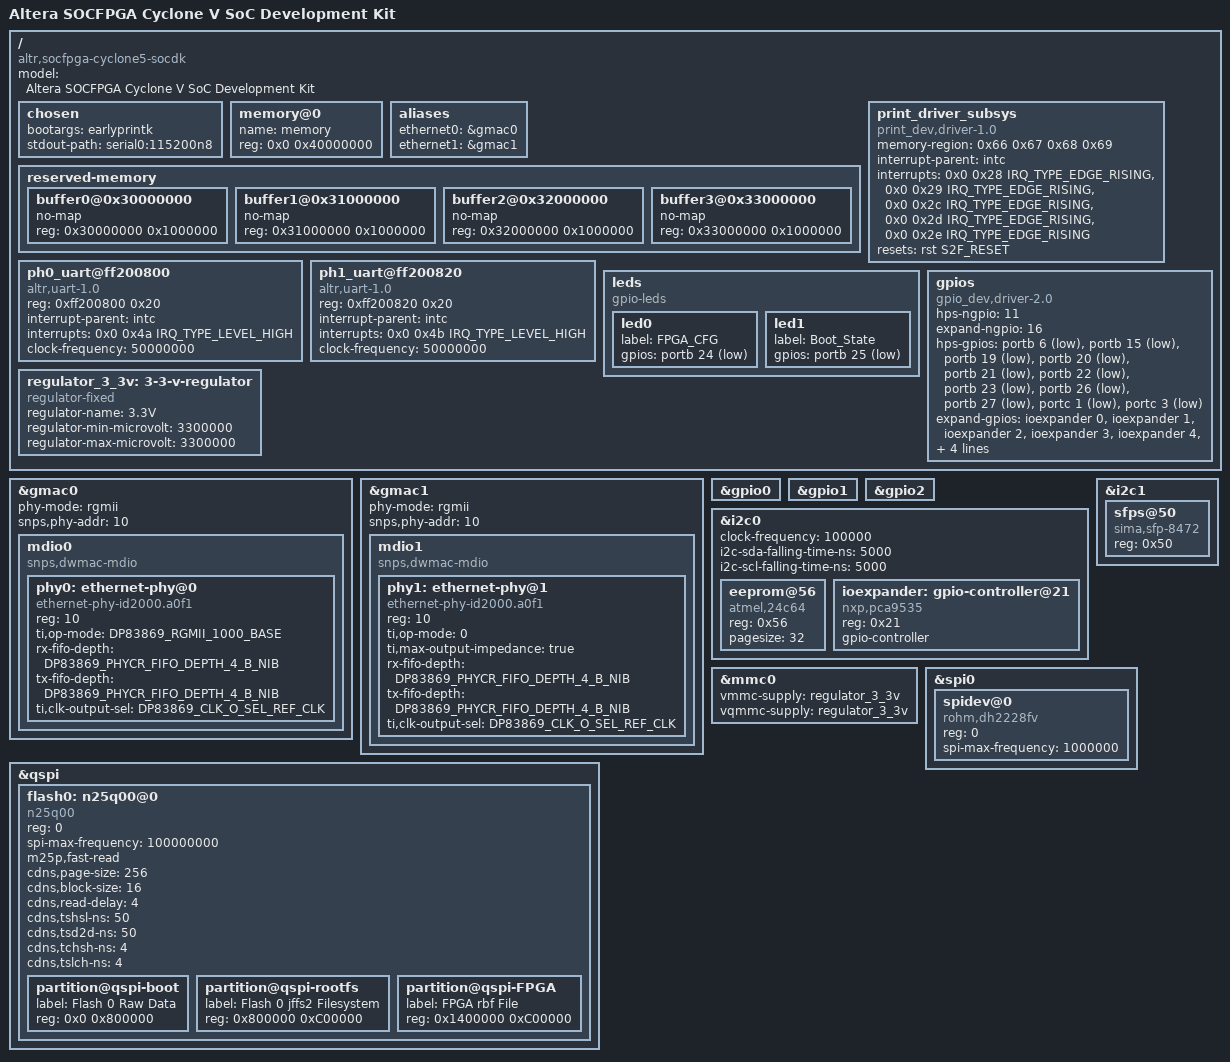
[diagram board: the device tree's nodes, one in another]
// SPDX-License-Identifier: GPL-2.0+
/*
 * Copyright (C) 2012 Altera Corporation <www.altera.com>
 */

#include "socfpga_cyclone5.dtsi"

#include <dt-bindings/gpio/gpio.h>
#include <dt-bindings/net/ti-dp83869.h>
#include <dt-bindings/interrupt-controller/irq.h>

/ {
	model = "Altera SOCFPGA Cyclone V SoC Development Kit";
	compatible = "altr,socfpga-cyclone5-socdk", "altr,socfpga-cyclone5", "altr,socfpga";

	chosen {
		bootargs = "earlyprintk";
		stdout-path = "serial0:115200n8";
	};

	memory@0 {
		name = "memory";
		device_type = "memory";
		reg = <0x0 0x40000000>; /* 1GB */
	};

	aliases {
		/* this allow the ethaddr uboot environmnet variable contents
		 * to be added to the gmac1 device tree blob.
		 */
		ethernet0 = &gmac0;
		ethernet1 = &gmac1;
	};

	reserved-memory {
		#address-cells = <0x1>;
		#size-cells = <0x1>;
		ranges;

		/* 上行ph0 */
		buffer0@0x30000000 {
			no-map;
			reg = <0x30000000 0x1000000>;
			linux,phandle = <0x66>;
			phandle = <0x66>;
		};
		
		/* 上行ph1 */
		buffer1@0x31000000 {
			no-map;
			reg = <0x31000000 0x1000000>;
			linux,phandle = <0x67>;
			phandle = <0x67>;
		};

		/* 下行ph0 */
		buffer2@0x32000000 {
			no-map;
			reg = <0x32000000 0x1000000>;
			linux,phandle = <0x68>;
			phandle = <0x68>;
		};

		/* 下行ph1 */
		buffer3@0x33000000 {
			no-map;
			reg = <0x33000000 0x1000000>;
			linux,phandle = <0x69>;
			phandle = <0x69>;
		};		
	};	

	print_driver_subsys {
		compatible = "print_dev,driver-1.0";
		memory-region = <0x66 0x67 0x68 0x69>;
		interrupt-parent = <&intc>;
		interrupts = <0x0 0x28 IRQ_TYPE_EDGE_RISING>,
					 <0x0 0x29 IRQ_TYPE_EDGE_RISING>,
					 <0x0 0x2c IRQ_TYPE_EDGE_RISING>,
					 <0x0 0x2d IRQ_TYPE_EDGE_RISING>,
					 <0x0 0x2e IRQ_TYPE_EDGE_RISING>;
		interrupt-names = "irq0-0", 
						  "irq0-1", 
						  "irq0-4", 
						  "irq0-5",
						  "irq0-6";
		resets = <&rst S2F_RESET>;
	};

	/* altera uart soft ip */
	ph0_uart@ff200800 {
		compatible = "altr,uart-1.0";	//altera-uart.c
		reg = <0xff200800 0x20>;
		interrupt-parent = <&intc>;
		interrupts = <0x0 0x4a IRQ_TYPE_LEVEL_HIGH>;	//fpga-irq34,发送和接收公用
		interrupt-names = "altera_uart0";	
		clock-frequency = <50000000>;
	};	
	ph1_uart@ff200820 {
		compatible = "altr,uart-1.0";
		reg = <0xff200820 0x20>;
		interrupt-parent = <&intc>;
		interrupts = <0x0 0x4b IRQ_TYPE_LEVEL_HIGH>;	//fpga-irq35,发送和接收公用
		interrupt-names = "altera_uart1";
		clock-frequency = <50000000>;
	};	
	

	leds {
		compatible = "gpio-leds";	//leds-gpio.c
		led0 {	
			label = "FPGA_CFG";
			gpios = <&portb 24 GPIO_ACTIVE_LOW>;
		};     
		led1 {
			label = "Boot_State";
			gpios = <&portb 25 GPIO_ACTIVE_LOW>;
		};
	};	

	gpios {
        compatible = "gpio_dev,driver-2.0";
		hps-ngpio = <11>;
		expand-ngpio = <16>;
		
        hps-gpios = 
			<&portb 6 GPIO_ACTIVE_LOW>,		/* lock_chip_en */
			<&portb 15 GPIO_ACTIVE_LOW>,    /* sdcard_instruct占用sd卡 */
			<&portb 19 GPIO_ACTIVE_LOW>,    /* 24v_en */
			<&portb 20 GPIO_ACTIVE_LOW>,   	/* ph_en */
			<&portb 21 GPIO_ACTIVE_LOW>, 	/* reserve */ 
			<&portb 22 GPIO_ACTIVE_LOW>,    /* ic_en */
			<&portb 23 GPIO_ACTIVE_LOW>, 	/* board_index */  
			<&portb 26 GPIO_ACTIVE_LOW>,   	/* phy1_init */ 
			<&portb 27 GPIO_ACTIVE_LOW>,    /* phy2_init */
			<&portc 1 GPIO_ACTIVE_LOW>,   	/* pca9535_init */ 
			<&portc 3 GPIO_ACTIVE_LOW>;    	/* los_index */

		expand-gpios = 
			<&ioexpander 0 GPIO_ACTIVE_HIGH>,	
			<&ioexpander 1 GPIO_ACTIVE_HIGH>,
			<&ioexpander 2 GPIO_ACTIVE_HIGH>,	
			<&ioexpander 3 GPIO_ACTIVE_HIGH>,
			<&ioexpander 4 GPIO_ACTIVE_HIGH>,	
			<&ioexpander 5 GPIO_ACTIVE_HIGH>,
			<&ioexpander 6 GPIO_ACTIVE_HIGH>,	
			<&ioexpander 7 GPIO_ACTIVE_HIGH>,	
			<&ioexpander 8 GPIO_ACTIVE_HIGH>,	
			<&ioexpander 9 GPIO_ACTIVE_HIGH>,
			<&ioexpander 10 GPIO_ACTIVE_HIGH>,	
			<&ioexpander 11 GPIO_ACTIVE_HIGH>,
			<&ioexpander 12 GPIO_ACTIVE_HIGH>,	
			<&ioexpander 13 GPIO_ACTIVE_HIGH>,
			<&ioexpander 14 GPIO_ACTIVE_HIGH>,	
			<&ioexpander 15 GPIO_ACTIVE_HIGH>;			
	};	

	regulator_3_3v: 3-3-v-regulator {
		compatible = "regulator-fixed";
		regulator-name = "3.3V";
		regulator-min-microvolt = <3300000>;
		regulator-max-microvolt = <3300000>;
	};
};

/* 光口 */
&gmac0 {		//socfpga-dwmac.txt  snps,dwmac.yaml socfpga-dwmac.c
    status = "okay";
    phy-mode = "rgmii";
	snps,phy-addr = <10>;	
	mdio0 {
        compatible = "snps,dwmac-mdio";		
        #address-cells = <1>;
        #size-cells = <0>;
		/* dp83869hw */
        phy0: ethernet-phy@0 {		//ti,dp83869.yaml dp83869.c
        	compatible = "ethernet-phy-id2000.a0f1";	
        	reg = <10>;
			ti,op-mode = <DP83869_RGMII_1000_BASE>;
			rx-fifo-depth = <DP83869_PHYCR_FIFO_DEPTH_4_B_NIB>;
			tx-fifo-depth = <DP83869_PHYCR_FIFO_DEPTH_4_B_NIB>;
            ti,clk-output-sel = <DP83869_CLK_O_SEL_REF_CLK>;
        };
	};
};

/* 电口 */
&gmac1 {
	status = "okay";
	phy-mode = "rgmii";
	snps,phy-addr = <10>;		
	mdio1 {
        compatible = "snps,dwmac-mdio";
        #address-cells = <1>;
        #size-cells = <0>;
		/* dp83869hw */
        phy1: ethernet-phy@1 {
            compatible = "ethernet-phy-id2000.a0f1";
			reg = <10>;			
			ti,op-mode = <0>;	
			ti,max-output-impedance = "true";
			rx-fifo-depth = <DP83869_PHYCR_FIFO_DEPTH_4_B_NIB>;
			tx-fifo-depth = <DP83869_PHYCR_FIFO_DEPTH_4_B_NIB>;
            ti,clk-output-sel = <DP83869_CLK_O_SEL_REF_CLK>;
        };
	};
};

&gpio0 {
	status = "okay";
};


&gpio1 {
	status = "okay";
};

&gpio2 {
	status = "okay";
};

&i2c0 {
	status = "okay";
	clock-frequency = <100000>;

	/*
	 * adjust the falling times to decrease the i2c frequency to 50Khz
	 * because the LCD module does not work at the standard 100Khz
	 */
	i2c-sda-falling-time-ns = <5000>;
	i2c-scl-falling-time-ns = <5000>;

	eeprom@56 {
		compatible = "atmel,24c64";
		reg = <0x56>;
		pagesize = <32>;
	};

	ioexpander: gpio-controller@21 {
		compatible = "nxp,pca9535";
		reg = <0x21>;
		gpio-controller;
		#gpio-cells = <2>;
	};
};

&i2c1 {
	status = "okay";

	sfps@50 {
		compatible = "sima,sfp-8472";
		reg = <0x50>;
	};
};

&mmc0 {
	//cd-gpios = <&portb 15 GPIO_ACTIVE_HIGH>;
	vmmc-supply = <&regulator_3_3v>;
	vqmmc-supply = <&regulator_3_3v>;
	status = "okay";
};

&qspi {
	status = "okay";

	flash0: n25q00@0 {
		#address-cells = <1>;
		#size-cells = <1>;
		compatible = "n25q00";
		reg = <0>;	/* chip select */
		spi-max-frequency = <100000000>;

		m25p,fast-read;
		cdns,page-size = <256>;
		cdns,block-size = <16>;
		cdns,read-delay = <4>;
		cdns,tshsl-ns = <50>;
		cdns,tsd2d-ns = <50>;
		cdns,tchsh-ns = <4>;
		cdns,tslch-ns = <4>;

		partition@qspi-boot {
            /* 8MB for raw data. */
            label = "Flash 0 Raw Data";
            reg = <0x0 0x800000>;
        };

        partition@qspi-rootfs {
            /* 12MB for jffs2 data. */
            label = "Flash 0 jffs2 Filesystem";
            reg = <0x800000 0xC00000>;
        };
        partition@qspi-FPGA {
            /* 12MB for rbf data. */
            label = "FPGA rbf File";
            reg = <0x1400000 0xC00000>;
        };
	};
};

&spi0 {
	status = "okay";

	spidev@0 {
		compatible = "rohm,dh2228fv";
		reg = <0>;
		spi-max-frequency = <1000000>;
	};
};
